# LRFDMDM register map
Vendor: Texas Instruments
Registers are 32-bit, access per field, reset 0x0 unless marked. A register's access mark holds for its fields unless they carry their own. Offsets are as the file gives them; [hi:lo] are bit positions; {n}, {i} and the like mark numbered series; 'fields as' and 'values as' point back to an identical list.

## LRFDMDM (part 2 of 3)
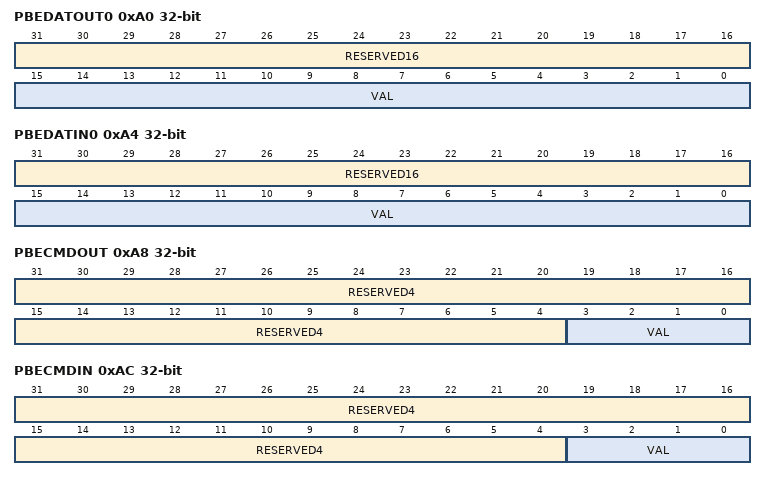
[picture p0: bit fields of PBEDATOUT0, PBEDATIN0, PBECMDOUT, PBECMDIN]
0xA0 PBEDATOUT0 — Internal. Only to be used through TI provided API.
  [31:16] RESERVED16 ro — Internal. Only to be used through TI provided API.
  [15:0] VAL rw — Internal. Only to be used through TI provided API.
    0xFFFF=ALLONES (Internal. Only to be used through TI provided API.); 0=ALLZEROS (Internal. Only to be used through TI provided API.)
0xA4 PBEDATIN0 ro — Internal. Only to be used through TI provided API.
  [31:16] RESERVED16 — Internal. Only to be used through TI provided API.
  [15:0] VAL — Internal. Only to be used through TI provided API.
    values as PBEDATOUT0.VAL
0xA8 PBECMDOUT — Internal. Only to be used through TI provided API.
  [31:4] RESERVED4 ro — Internal. Only to be used through TI provided API.
  [3:0] VAL rw — Internal. Only to be used through TI provided API.
    15=ALLONES (Internal. Only to be used through TI provided API.); 0=ALLZEROS (Internal. Only to be used through TI provided API.)
0xAC PBECMDIN ro — Internal. Only to be used through TI provided API.
  [31:4] RESERVED4 — Internal. Only to be used through TI provided API.
  [3:0] VAL — Internal. Only to be used through TI provided API.
    values as PBECMDOUT.VAL
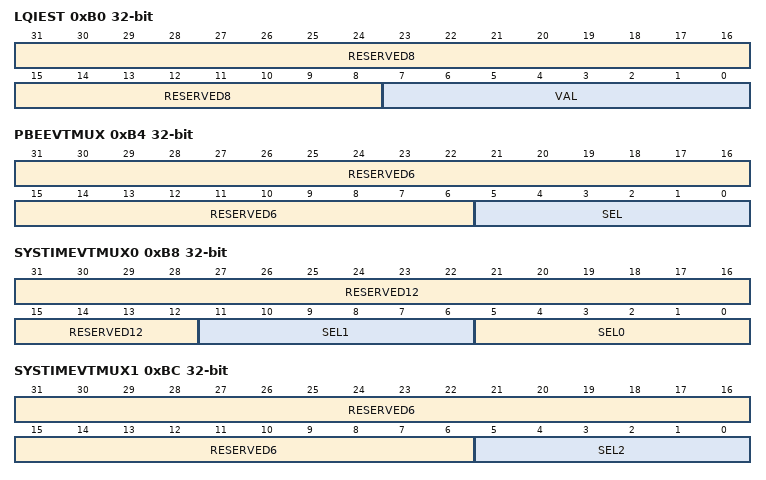
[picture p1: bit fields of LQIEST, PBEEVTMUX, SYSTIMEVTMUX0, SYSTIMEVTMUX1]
0xB0 LQIEST — Internal. Only to be used through TI provided API.
  [31:8] RESERVED8 ro — Internal. Only to be used through TI provided API.
  [7:0] VAL rw — Internal. Only to be used through TI provided API.
    255=ALLONES (Internal. Only to be used through TI provided API.); 0=ALLZEROS (Internal. Only to be used through TI provided API.)
0xB4 PBEEVTMUX — Internal. Only to be used through TI provided API.
  [31:6] RESERVED6 ro — Internal. Only to be used through TI provided API.
  [5:0] SEL rw — Internal. Only to be used through TI provided API.
    63=ALLONES (Internal. Only to be used through TI provided API.); 0=ALLZEROS (Internal. Only to be used through TI provided API.)
0xB8 SYSTIMEVTMUX0 — Internal. Only to be used through TI provided API.
  [31:12] RESERVED12 ro — Internal. Only to be used through TI provided API.
  [11:6] SEL1 rw — Internal. Only to be used through TI provided API.
    values as PBEEVTMUX.SEL
  [5:0] SEL0 rw — Internal. Only to be used through TI provided API.
    values as PBEEVTMUX.SEL
0xBC SYSTIMEVTMUX1 — Internal. Only to be used through TI provided API.
  [31:6] RESERVED6 ro — Internal. Only to be used through TI provided API.
  [5:0] SEL2 rw — Internal. Only to be used through TI provided API.
    values as PBEEVTMUX.SEL
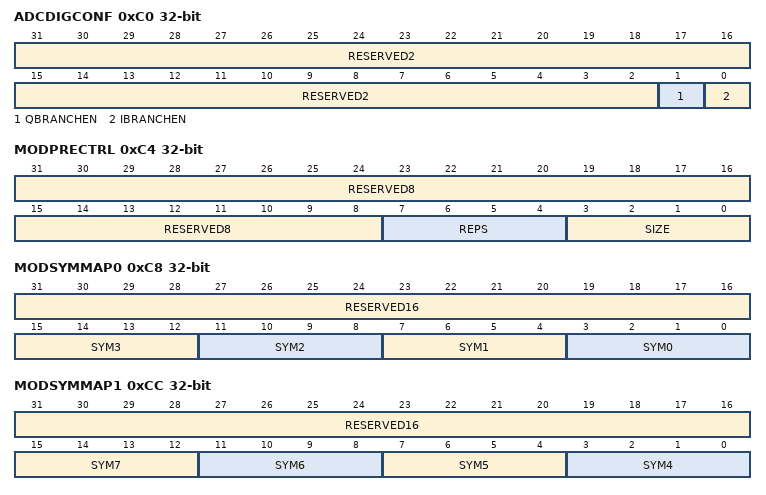
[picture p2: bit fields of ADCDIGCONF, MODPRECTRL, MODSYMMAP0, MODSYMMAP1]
0xC0 ADCDIGCONF — Internal. Only to be used through TI provided API.
  [31:2] RESERVED2 ro — Internal. Only to be used through TI provided API.
  [1] QBRANCHEN rw — Internal. Only to be used through TI provided API.
    1=ON (Internal. Only to be used through TI provided API.); 0=OFF (Internal. Only to be used through TI provided API.)
  [0] IBRANCHEN rw — Internal. Only to be used through TI provided API.
    values as QBRANCHEN
0xC4 MODPRECTRL — Internal. Only to be used through TI provided API.
  [31:8] RESERVED8 ro — Internal. Only to be used through TI provided API.
  [7:4] REPS rw — Internal. Only to be used through TI provided API.
    {v}=Internal. Only to be used through TI provided API. (v=0..15)
  [3:0] SIZE rw — Internal. Only to be used through TI provided API.
    15=BITS16 (Internal. Only to be used through TI provided API.); 7=BITS8 (Internal. Only to be used through TI provided API.); 3=BITS4 (Internal. Only to be used through TI provided API.)
0xC8 MODSYMMAP0 — Internal. Only to be used through TI provided API.
  [31:16] RESERVED16 ro — Internal. Only to be used through TI provided API.
  [4n+3:4n] SYM{n} rw (n=0..3) — Internal. Only to be used through TI provided API.
    values as PBECMDOUT.VAL
0xCC MODSYMMAP1 — Internal. Only to be used through TI provided API.
  [31:16] RESERVED16 ro — Internal. Only to be used through TI provided API.
  [4n-13:4n-16] SYM{n} rw (n=4..7) — Internal. Only to be used through TI provided API.
    values as PBECMDOUT.VAL
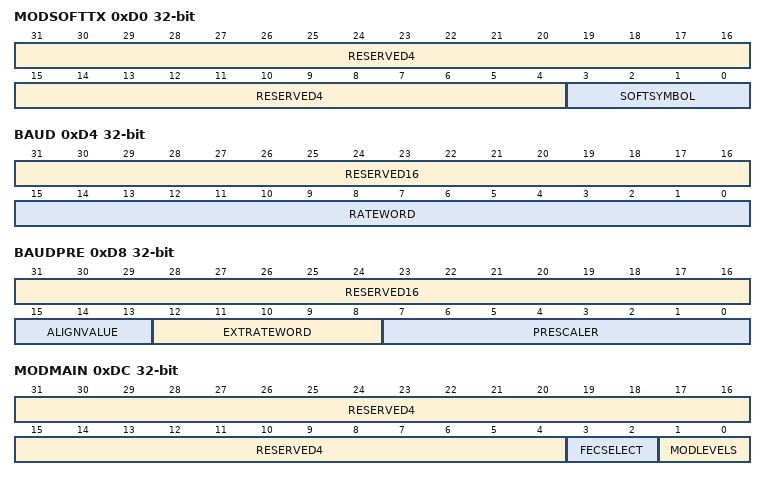
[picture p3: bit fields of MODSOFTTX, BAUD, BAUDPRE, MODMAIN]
0xD0 MODSOFTTX — Internal. Only to be used through TI provided API.
  [31:4] RESERVED4 ro — Internal. Only to be used through TI provided API.
  [3:0] SOFTSYMBOL rw — Internal. Only to be used through TI provided API.
    values as PBECMDOUT.VAL
0xD4 BAUD — Internal. Only to be used through TI provided API.
  [31:16] RESERVED16 ro — Internal. Only to be used through TI provided API.
  [15:0] RATEWORD rw — Internal. Only to be used through TI provided API.
    values as PBEDATOUT0.VAL
0xD8 BAUDPRE — Internal. Only to be used through TI provided API.
  [31:16] RESERVED16 ro — Internal. Only to be used through TI provided API.
  [15:13] ALIGNVALUE rw — Internal. Only to be used through TI provided API.
    7=ALLONES (Internal. Only to be used through TI provided API.); 0=ALLZEROS (Internal. Only to be used through TI provided API.)
  [12:8] EXTRATEWORD rw — Internal. Only to be used through TI provided API.
    31=ALLONES (Internal. Only to be used through TI provided API.); 0=ALLZEROS (Internal. Only to be used through TI provided API.)
  [7:0] PRESCALER rw — Internal. Only to be used through TI provided API.
    values as LQIEST.VAL
0xDC MODMAIN — Internal. Only to be used through TI provided API.
  [31:4] RESERVED4 ro — Internal. Only to be used through TI provided API.
  [3:2] FECSELECT rw — Internal. Only to be used through TI provided API.
    3=BLR (Internal. Only to be used through TI provided API.); 2=RESERVED (Internal. Only to be used through TI provided API.); 1=IEEE15_4 (Internal. Only to be used through TI provided API.); 0=NOSEL (Internal. Only to be used through TI provided API.)
  [1:0] MODLEVELS rw — Internal. Only to be used through TI provided API.
    2=LVL8 (Internal. Only to be used through TI provided API.); 1=LVL4 (Internal. Only to be used through TI provided API.); 0=LVL2 (Internal. Only to be used through TI provided API.)
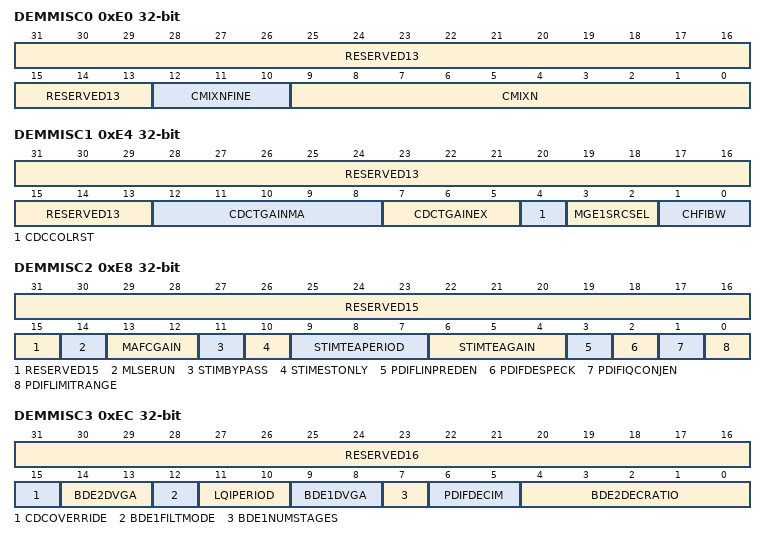
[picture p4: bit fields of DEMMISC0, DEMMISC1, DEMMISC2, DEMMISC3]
0xE0 DEMMISC0 — Internal. Only to be used through TI provided API.
  [31:13] RESERVED13 ro — Internal. Only to be used through TI provided API.
  [12:10] CMIXNFINE rw — Internal. Only to be used through TI provided API.
  [9:0] CMIXN rw — Internal. Only to be used through TI provided API.
    0x3FF=ALLONES (Internal. Only to be used through TI provided API.); 0=ALLZEROS (Internal. Only to be used through TI provided API.)
0xE4 DEMMISC1 — Internal. Only to be used through TI provided API.
  [31:13] RESERVED13 ro — Internal. Only to be used through TI provided API.
  [12:8] CDCTGAINMA rw — Internal. Only to be used through TI provided API.
    values as BAUDPRE.EXTRATEWORD
  [7:5] CDCTGAINEX rw — Internal. Only to be used through TI provided API.
    values as BAUDPRE.ALIGNVALUE
  [4] CDCCOLRST rw — Internal. Only to be used through TI provided API.
    1=EN (Internal. Only to be used through TI provided API.); 0=DIS (Internal. Only to be used through TI provided API.)
  [3:2] MGE1SRCSEL rw — Internal. Only to be used through TI provided API.
    2=CHFI (Internal. Only to be used through TI provided API.); 1=FEXB1 (Internal. Only to be used through TI provided API.); 0=FIDC (Internal. Only to be used through TI provided API.)
  [1:0] CHFIBW rw — Internal. Only to be used through TI provided API.
    3=BW0_29 (Internal. Only to be used through TI provided API.); 2=BW0_41667 (Internal. Only to be used through TI provided API.); 1=BW0_3333 (Internal. Only to be used through TI provided API.); 0=BW0_5 (Internal. Only to be used through TI provided API.)
0xE8 DEMMISC2 — Internal. Only to be used through TI provided API.
  [31:15] RESERVED15 ro — Internal. Only to be used through TI provided API.
  [14] MLSERUN rw — Internal. Only to be used through TI provided API.
    values as DEMMISC1.CDCCOLRST
  [13:12] MAFCGAIN rw — Internal. Only to be used through TI provided API.
    3=ALLONES (Internal. Only to be used through TI provided API.); 0=ALLZEROS (Internal. Only to be used through TI provided API.)
  [11] STIMBYPASS rw — Internal. Only to be used through TI provided API.
    values as DEMMISC1.CDCCOLRST
  [10] STIMESTONLY rw — Internal. Only to be used through TI provided API.
    values as DEMMISC1.CDCCOLRST
  [9:7] STIMTEAPERIOD rw — Internal. Only to be used through TI provided API.
    5=SYM128 (Internal. Only to be used through TI provided API.); 4=SYM64 (Internal. Only to be used through TI provided API.); 3=SYM32 (Internal. Only to be used through TI provided API.); 2=SYM16 (Internal. Only to be used through TI provided API.); 1=SYM8 (Internal. Only to be used through TI provided API.); 0=SYM4 (Internal. Only to be used through TI provided API.)
  [6:4] STIMTEAGAIN rw — Internal. Only to be used through TI provided API.
    7=DIV4 (Internal. Only to be used through TI provided API.); 6=DIV8 (Internal. Only to be used through TI provided API.); 5=DIV16 (Internal. Only to be used through TI provided API.); 4=DIV32 (Internal. Only to be used through TI provided API.); 3=DIV64 (Internal. Only to be used through TI provided API.); 2=DIV128 (Internal. Only to be used through TI provided API.); 1=DIV256 (Internal. Only to be used through TI provided API.); 0=DIV512 (Internal. Only to be used through TI provided API.)
  [3] PDIFLINPREDEN rw — Internal. Only to be used through TI provided API.
    values as ADCDIGCONF.QBRANCHEN
  [2] PDIFDESPECK rw — Internal. Only to be used through TI provided API.
    values as DEMMISC1.CDCCOLRST
  [1] PDIFIQCONJEN rw — Internal. Only to be used through TI provided API.
    values as ADCDIGCONF.QBRANCHEN
  [0] PDIFLIMITRANGE rw — Internal. Only to be used through TI provided API.
    values as DEMMISC1.CDCCOLRST
0xEC DEMMISC3 — Internal. Only to be used through TI provided API.
  [31:16] RESERVED16 ro — Internal. Only to be used through TI provided API.
  [15] CDCOVERRIDE rw — Internal. Only to be used through TI provided API.
  [14:13] BDE2DVGA rw — Internal. Only to be used through TI provided API.
    3=GAIN8 (Internal. Only to be used through TI provided API.); 2=GAIN4 (Internal. Only to be used through TI provided API.); 1=GAIN2 (Internal. Only to be used through TI provided API.); 0=GAIN1 (Internal. Only to be used through TI provided API.)
  [12] BDE1FILTMODE rw — Internal. Only to be used through TI provided API.
    1=DIV2 (Internal. Only to be used through TI provided API.); 0=DIV1 (Internal. Only to be used through TI provided API.)
  [11:10] LQIPERIOD rw — Internal. Only to be used through TI provided API.
    3=SYM1024 (Internal. Only to be used through TI provided API.); 2=SYM256 (Internal. Only to be used through TI provided API.); 1=SYM64 (Internal. Only to be used through TI provided API.); 0=SYM16 (Internal. Only to be used through TI provided API.)
  [9:8] BDE1DVGA rw — Internal. Only to be used through TI provided API.
    values as BDE2DVGA
  [7] BDE1NUMSTAGES rw — Internal. Only to be used through TI provided API.
    values as BDE1FILTMODE
  [6:5] PDIFDECIM rw — Internal. Only to be used through TI provided API.
    2=DIV4 (Internal. Only to be used through TI provided API.); 1=DIV2 (Internal. Only to be used through TI provided API.); 0=DIV1 (Internal. Only to be used through TI provided API.)
  [4:0] BDE2DECRATIO rw — Internal. Only to be used through TI provided API.
    3=DIV8 (Internal. Only to be used through TI provided API.); 2=DIV4 (Internal. Only to be used through TI provided API.); 1=DIV2 (Internal. Only to be used through TI provided API.); 0=DIV1 (Internal. Only to be used through TI provided API.)
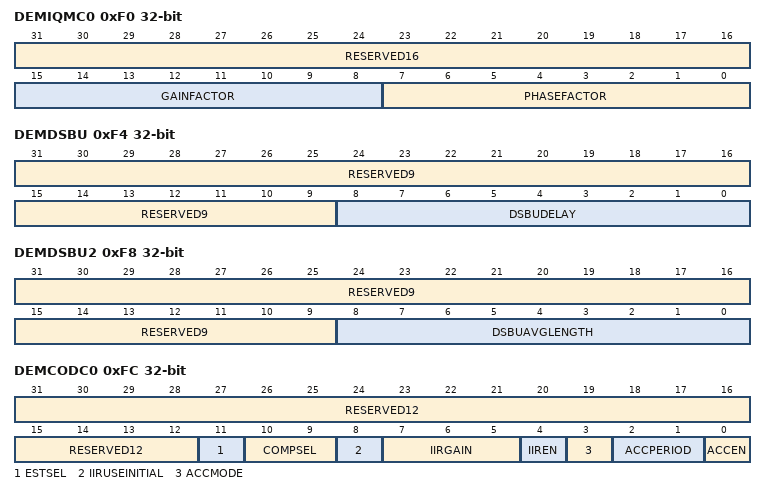
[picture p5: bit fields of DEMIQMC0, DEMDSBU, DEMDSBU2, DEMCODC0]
0xF0 DEMIQMC0 — Internal. Only to be used through TI provided API.
  [31:16] RESERVED16 ro — Internal. Only to be used through TI provided API.
  [15:8] GAINFACTOR rw — Internal. Only to be used through TI provided API.
    values as LQIEST.VAL
  [7:0] PHASEFACTOR rw — Internal. Only to be used through TI provided API.
    values as LQIEST.VAL
0xF4 DEMDSBU — Internal. Only to be used through TI provided API.
  [31:9] RESERVED9 ro — Internal. Only to be used through TI provided API.
  [8:0] DSBUDELAY rw — Internal. Only to be used through TI provided API.
    values as LQIEST.VAL
0xF8 DEMDSBU2 — Internal. Only to be used through TI provided API.
  [31:9] RESERVED9 ro — Internal. Only to be used through TI provided API.
  [8:0] DSBUAVGLENGTH rw — Internal. Only to be used through TI provided API.
0xFC DEMCODC0 — Internal. Only to be used through TI provided API.
  [31:12] RESERVED12 ro — Internal. Only to be used through TI provided API.
  [11] ESTSEL rw — Internal. Only to be used through TI provided API.
    1=IIR (Internal. Only to be used through TI provided API.); 0=ACC (Internal. Only to be used through TI provided API.)
  [10:9] COMPSEL rw — Internal. Only to be used through TI provided API.
    3=IIR (Internal. Only to be used through TI provided API.); 2=ACC (Internal. Only to be used through TI provided API.); 0=MANUAL (Internal. Only to be used through TI provided API.)
  [8] IIRUSEINITIAL rw — Internal. Only to be used through TI provided API.
    values as DEMMISC1.CDCCOLRST
  [7:5] IIRGAIN rw — Internal. Only to be used through TI provided API.
    7=DIV1024 (Internal. Only to be used through TI provided API.); 6=DIV512 (Internal. Only to be used through TI provided API.); 5=DIV256 (Internal. Only to be used through TI provided API.); 4=DIV128 (Internal. Only to be used through TI provided API.); 3=DIV64 (Internal. Only to be used through TI provided API.); 2=DIV32 (Internal. Only to be used through TI provided API.); 1=DIV16 (Internal. Only to be used through TI provided API.); 0=OFF (Internal. Only to be used through TI provided API.)
  [4] IIREN rw — Internal. Only to be used through TI provided API.
    values as ADCDIGCONF.QBRANCHEN
  [3] ACCMODE rw — Internal. Only to be used through TI provided API.
    1=CONT (Internal. Only to be used through TI provided API.); 0=SINGLE (Internal. Only to be used through TI provided API.)
  [2:1] ACCPERIOD rw — Internal. Only to be used through TI provided API.
    3=SMPL512 (Internal. Only to be used through TI provided API.); 2=SMPL128 (Internal. Only to be used through TI provided API.); 1=SMPL32 (Internal. Only to be used through TI provided API.); 0=SMPL8 (Internal. Only to be used through TI provided API.)
  [0] ACCEN rw — Internal. Only to be used through TI provided API.
    values as ADCDIGCONF.QBRANCHEN
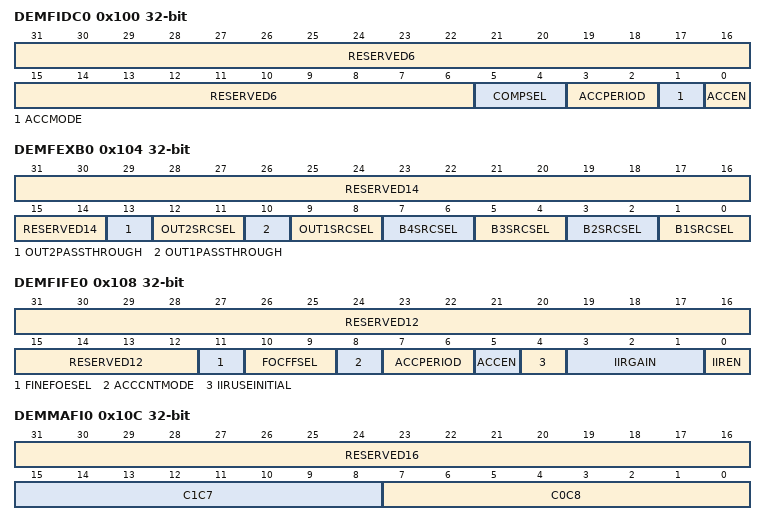
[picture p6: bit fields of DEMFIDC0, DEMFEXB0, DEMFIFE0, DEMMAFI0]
0x100 DEMFIDC0 — Internal. Only to be used through TI provided API.
  [31:6] RESERVED6 ro — Internal. Only to be used through TI provided API.
  [5:4] COMPSEL rw — Internal. Only to be used through TI provided API.
    2=ACC (Internal. Only to be used through TI provided API.); 0=MANUAL (Internal. Only to be used through TI provided API.)
  [3:2] ACCPERIOD rw — Internal. Only to be used through TI provided API.
    values as DEMCODC0.ACCPERIOD
  [1] ACCMODE rw — Internal. Only to be used through TI provided API.
    values as DEMCODC0.ACCMODE
  [0] ACCEN rw — Internal. Only to be used through TI provided API.
    values as ADCDIGCONF.QBRANCHEN
0x104 DEMFEXB0 — Internal. Only to be used through TI provided API.
  [31:14] RESERVED14 ro — Internal. Only to be used through TI provided API.
  [13] OUT2PASSTHROUGH rw — Internal. Only to be used through TI provided API.
    1=ONE (Internal. Only to be used through TI provided API.); 0=ZERO (Internal. Only to be used through TI provided API.)
  [12:11] OUT2SRCSEL rw — Internal. Only to be used through TI provided API.
    2=BDE1 (Internal. Only to be used through TI provided API.); 1=CMIX (Internal. Only to be used through TI provided API.); 0=CODC (Internal. Only to be used through TI provided API.)
  [10] OUT1PASSTHROUGH rw — Internal. Only to be used through TI provided API.
    values as OUT2PASSTHROUGH
  [9:8] OUT1SRCSEL rw — Internal. Only to be used through TI provided API.
    values as OUT2SRCSEL
  [7:6] B4SRCSEL rw — Internal. Only to be used through TI provided API.
    3=ONES (Internal. Only to be used through TI provided API.); 0=ZEROS (Internal. Only to be used through TI provided API.)
  [5:4] B3SRCSEL rw — Internal. Only to be used through TI provided API.
    2=CMIX (Internal. Only to be used through TI provided API.); 1=CODC (Internal. Only to be used through TI provided API.); 0=INPUT (Internal. Only to be used through TI provided API.)
  [3:2] B2SRCSEL rw — Internal. Only to be used through TI provided API.
    2=BDE1 (Internal. Only to be used through TI provided API.); 1=CODC (Internal. Only to be used through TI provided API.); 0=INPUT (Internal. Only to be used through TI provided API.)
  [1:0] B1SRCSEL rw — Internal. Only to be used through TI provided API.
    2=BDE1 (Internal. Only to be used through TI provided API.); 1=CMIX (Internal. Only to be used through TI provided API.); 0=INPUT (Internal. Only to be used through TI provided API.)
0x108 DEMFIFE0 — Internal. Only to be used through TI provided API.
  [31:12] RESERVED12 ro — Internal. Only to be used through TI provided API.
  [11] FINEFOESEL rw — Internal. Only to be used through TI provided API.
    1=ACC (Internal. Only to be used through TI provided API.); 0=IIR (Internal. Only to be used through TI provided API.)
  [10:9] FOCFFSEL rw — Internal. Only to be used through TI provided API.
    2=MANUAL (Internal. Only to be used through TI provided API.); 1=ACC (Internal. Only to be used through TI provided API.); 0=IIR (Internal. Only to be used through TI provided API.)
  [8] ACCCNTMODE rw — Internal. Only to be used through TI provided API.
    values as DEMCODC0.ACCMODE
  [7:6] ACCPERIOD rw — Internal. Only to be used through TI provided API.
    3=PER512 (Internal. Only to be used through TI provided API.); 2=PER256 (Internal. Only to be used through TI provided API.); 1=PER128 (Internal. Only to be used through TI provided API.); 0=PER64 (Internal. Only to be used through TI provided API.)
  [5] ACCEN rw — Internal. Only to be used through TI provided API.
    values as ADCDIGCONF.QBRANCHEN
  [4] IIRUSEINITIAL rw — Internal. Only to be used through TI provided API.
    values as DEMMISC1.CDCCOLRST
  [3:1] IIRGAIN rw — Internal. Only to be used through TI provided API.
    values as DEMCODC0.IIRGAIN
  [0] IIREN rw — Internal. Only to be used through TI provided API.
    values as ADCDIGCONF.QBRANCHEN
0x10C DEMMAFI0 — Internal. Only to be used through TI provided API.
  [31:16] RESERVED16 ro — Internal. Only to be used through TI provided API.
  [15:8] C1C7 rw — Internal. Only to be used through TI provided API.
    values as LQIEST.VAL
  [7:0] C0C8 rw — Internal. Only to be used through TI provided API.
    values as LQIEST.VAL
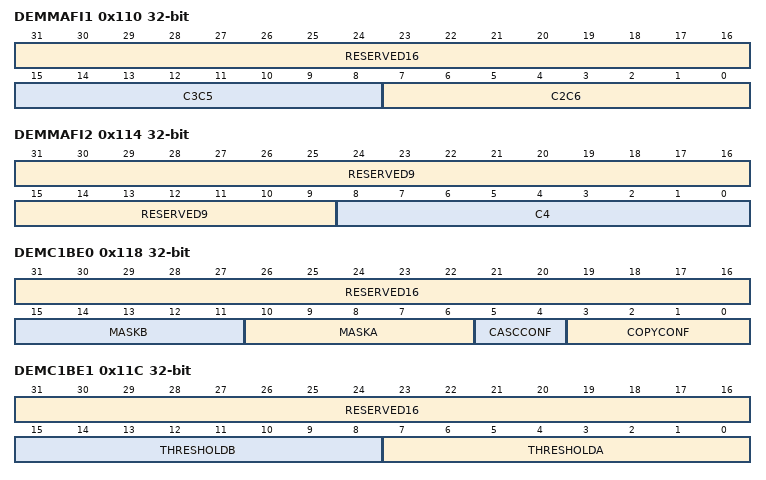
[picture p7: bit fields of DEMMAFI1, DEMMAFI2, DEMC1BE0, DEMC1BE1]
0x110 DEMMAFI1 — Internal. Only to be used through TI provided API.
  [31:16] RESERVED16 ro — Internal. Only to be used through TI provided API.
  [15:8] C3C5 rw — Internal. Only to be used through TI provided API.
    values as LQIEST.VAL
  [7:0] C2C6 rw — Internal. Only to be used through TI provided API.
    values as LQIEST.VAL
0x114 DEMMAFI2 — Internal. Only to be used through TI provided API.
  [31:9] RESERVED9 ro — Internal. Only to be used through TI provided API.
  [8:0] C4 rw — Internal. Only to be used through TI provided API.
    0x1FF=ALLONES (Internal. Only to be used through TI provided API.); 0=ALLZEROS (Internal. Only to be used through TI provided API.)
0x118 DEMC1BE0 — Internal. Only to be used through TI provided API.
  [31:16] RESERVED16 ro — Internal. Only to be used through TI provided API.
  [15:11] MASKB rw — Internal. Only to be used through TI provided API.
    values as BAUDPRE.EXTRATEWORD
  [10:6] MASKA rw — Internal. Only to be used through TI provided API.
    values as BAUDPRE.EXTRATEWORD
  [5:4] CASCCONF rw — Internal. Only to be used through TI provided API.
    2=PARALLEL (Internal. Only to be used through TI provided API.); 1=SERIAL (Internal. Only to be used through TI provided API.); 0=SINGLE (Internal. Only to be used through TI provided API.)
  [3:0] COPYCONF rw — Internal. Only to be used through TI provided API.
    values as PBECMDOUT.VAL
0x11C DEMC1BE1 — Internal. Only to be used through TI provided API.
  [31:16] RESERVED16 ro — Internal. Only to be used through TI provided API.
  [15:8] THRESHOLDB rw — Internal. Only to be used through TI provided API.
    values as LQIEST.VAL
  [7:0] THRESHOLDA rw — Internal. Only to be used through TI provided API.
    values as LQIEST.VAL
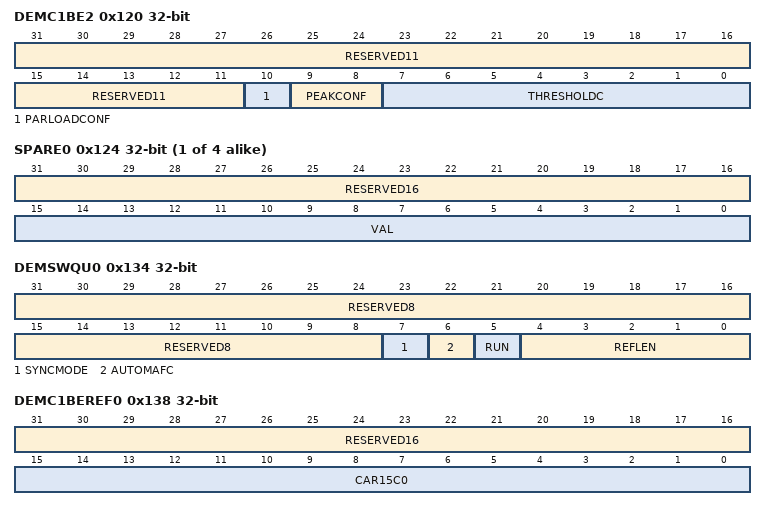
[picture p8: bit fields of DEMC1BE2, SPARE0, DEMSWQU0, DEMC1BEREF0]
0x120 DEMC1BE2 — Internal. Only to be used through TI provided API.
  [31:11] RESERVED11 ro — Internal. Only to be used through TI provided API.
  [10] PARLOADCONF rw — Internal. Only to be used through TI provided API.
    1=ATOD (Internal. Only to be used through TI provided API.); 0=ATOB (Internal. Only to be used through TI provided API.)
  [9:8] PEAKCONF rw — Internal. Only to be used through TI provided API.
    2=BESTAB (Internal. Only to be used through TI provided API.); 1=BEST (Internal. Only to be used through TI provided API.); 0=THRESH (Internal. Only to be used through TI provided API.)
  [7:0] THRESHOLDC rw — Internal. Only to be used through TI provided API.
    values as LQIEST.VAL
{0x124+4i} SPARE{i} (i=0..3) — Internal. Only to be used through TI provided API.
  fields as PBEDATOUT0
0x134 DEMSWQU0 — Internal. Only to be used through TI provided API.
  [31:8] RESERVED8 ro — Internal. Only to be used through TI provided API.
  [7] SYNCMODE rw — Internal. Only to be used through TI provided API.
    values as DEMFEXB0.OUT2PASSTHROUGH
  [6] AUTOMAFC rw — Internal. Only to be used through TI provided API.
    values as ADCDIGCONF.QBRANCHEN
  [5] RUN rw — Internal. Only to be used through TI provided API.
    values as ADCDIGCONF.QBRANCHEN
  [4:0] REFLEN rw — Internal. Only to be used through TI provided API.
    values as BAUDPRE.EXTRATEWORD
0x138 DEMC1BEREF0 — Internal. Only to be used through TI provided API.
  [31:16] RESERVED16 ro — Internal. Only to be used through TI provided API.
  [15:0] CAR15C0 rw — Internal. Only to be used through TI provided API.
    values as PBEDATOUT0.VAL
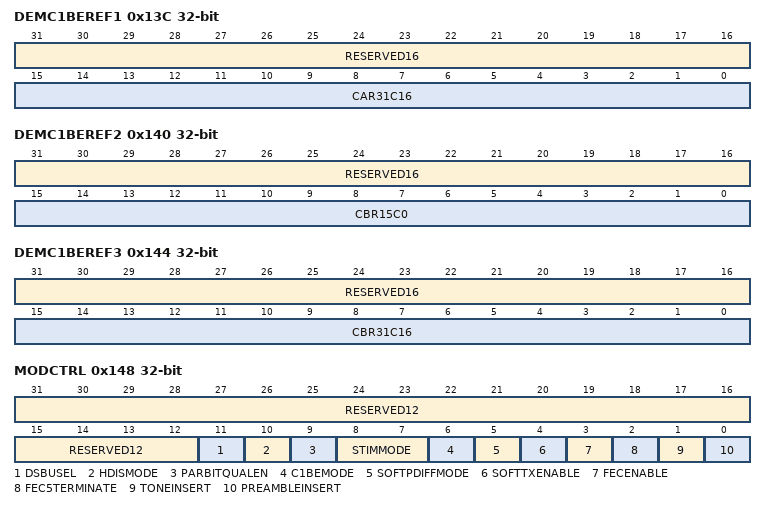
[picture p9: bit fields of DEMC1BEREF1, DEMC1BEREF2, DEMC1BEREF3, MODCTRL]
0x13C DEMC1BEREF1 — Internal. Only to be used through TI provided API.
  [31:16] RESERVED16 ro — Internal. Only to be used through TI provided API.
  [15:0] CAR31C16 rw — Internal. Only to be used through TI provided API.
    values as PBEDATOUT0.VAL
0x140 DEMC1BEREF2 — Internal. Only to be used through TI provided API.
  [31:16] RESERVED16 ro — Internal. Only to be used through TI provided API.
  [15:0] CBR15C0 rw — Internal. Only to be used through TI provided API.
    values as PBEDATOUT0.VAL
0x144 DEMC1BEREF3 — Internal. Only to be used through TI provided API.
  [31:16] RESERVED16 ro — Internal. Only to be used through TI provided API.
  [15:0] CBR31C16 rw — Internal. Only to be used through TI provided API.
    values as PBEDATOUT0.VAL
0x148 MODCTRL — Internal. Only to be used through TI provided API.
  [31:12] RESERVED12 ro — Internal. Only to be used through TI provided API.
  [11] DSBUSEL rw — Internal. Only to be used through TI provided API.
    values as DEMFEXB0.OUT2PASSTHROUGH
  [10] HDISMODE rw — Internal. Only to be used through TI provided API.
    values as DEMMISC1.CDCCOLRST
  [9] PARBITQUALEN rw — Internal. Only to be used through TI provided API.
    values as ADCDIGCONF.QBRANCHEN
  [8:7] STIMMODE rw — Internal. Only to be used through TI provided API.
    2=EARLY (Internal. Only to be used through TI provided API.); 1=LATE (Internal. Only to be used through TI provided API.); 0=NORMAL (Internal. Only to be used through TI provided API.)
  [6] C1BEMODE rw — Internal. Only to be used through TI provided API.
    1=EARLYLATE (Internal. Only to be used through TI provided API.); 0=NORMAL (Internal. Only to be used through TI provided API.)
  [5] SOFTPDIFFMODE rw — Internal. Only to be used through TI provided API.
    values as DEMMISC1.CDCCOLRST
  [4] SOFTTXENABLE rw — Internal. Only to be used through TI provided API.
    values as ADCDIGCONF.QBRANCHEN
  [3] FECENABLE rw — Internal. Only to be used through TI provided API.
    values as ADCDIGCONF.QBRANCHEN
  [2] FEC5TERMINATE rw — Internal. Only to be used through TI provided API.
    values as ADCDIGCONF.QBRANCHEN
  [1] TONEINSERT rw — Internal. Only to be used through TI provided API.
    values as DEMMISC1.CDCCOLRST
  [0] PREAMBLEINSERT rw — Internal. Only to be used through TI provided API.
    values as DEMMISC1.CDCCOLRST
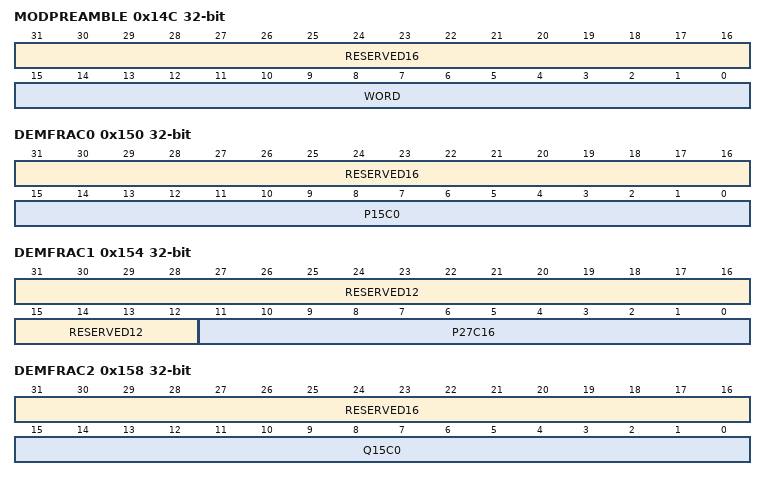
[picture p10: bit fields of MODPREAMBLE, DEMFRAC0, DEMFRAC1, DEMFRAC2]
0x14C MODPREAMBLE — Internal. Only to be used through TI provided API.
  [31:16] RESERVED16 ro — Internal. Only to be used through TI provided API.
  [15:0] WORD rw — Internal. Only to be used through TI provided API.
    values as PBEDATOUT0.VAL
0x150 DEMFRAC0 — Internal. Only to be used through TI provided API.
  [31:16] RESERVED16 ro — Internal. Only to be used through TI provided API.
  [15:0] P15C0 rw — Internal. Only to be used through TI provided API.
    values as PBEDATOUT0.VAL
0x154 DEMFRAC1 — Internal. Only to be used through TI provided API.
  [31:12] RESERVED12 ro — Internal. Only to be used through TI provided API.
  [11:0] P27C16 rw — Internal. Only to be used through TI provided API.
    0xFFF=ALLONES (Internal. Only to be used through TI provided API.); 0=ALLZEROS (Internal. Only to be used through TI provided API.)
0x158 DEMFRAC2 — Internal. Only to be used through TI provided API.
  [31:16] RESERVED16 ro — Internal. Only to be used through TI provided API.
  [15:0] Q15C0 rw — Internal. Only to be used through TI provided API.
    values as PBEDATOUT0.VAL
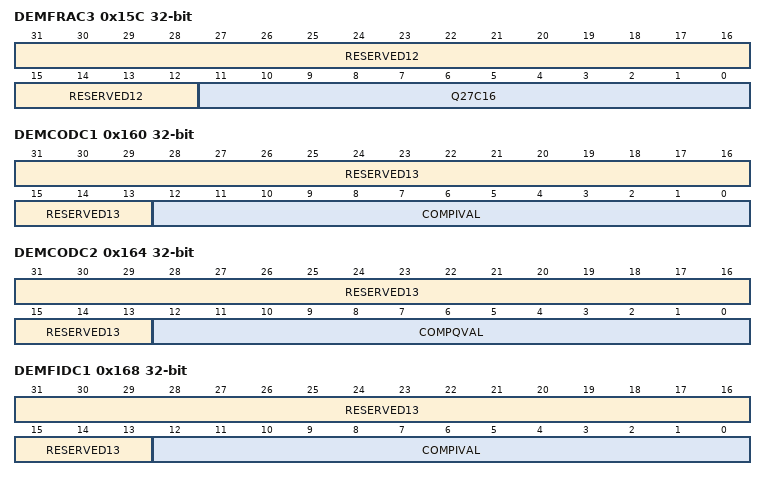
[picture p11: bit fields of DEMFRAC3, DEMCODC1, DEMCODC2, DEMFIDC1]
0x15C DEMFRAC3 — Internal. Only to be used through TI provided API.
  [31:12] RESERVED12 ro — Internal. Only to be used through TI provided API.
  [11:0] Q27C16 rw — Internal. Only to be used through TI provided API.
    values as DEMFRAC1.P27C16
0x160 DEMCODC1 — Internal. Only to be used through TI provided API.
  [31:13] RESERVED13 ro — Internal. Only to be used through TI provided API.
  [12:0] COMPIVAL rw — Internal. Only to be used through TI provided API.
    0x1FFF=ALLONES (Internal. Only to be used through TI provided API.); 0=ALLZEROS (Internal. Only to be used through TI provided API.)
0x164 DEMCODC2 — Internal. Only to be used through TI provided API.
  [31:13] RESERVED13 ro — Internal. Only to be used through TI provided API.
  [12:0] COMPQVAL rw — Internal. Only to be used through TI provided API.
    values as DEMCODC1.COMPIVAL
0x168 DEMFIDC1 — Internal. Only to be used through TI provided API.
  fields as DEMCODC1
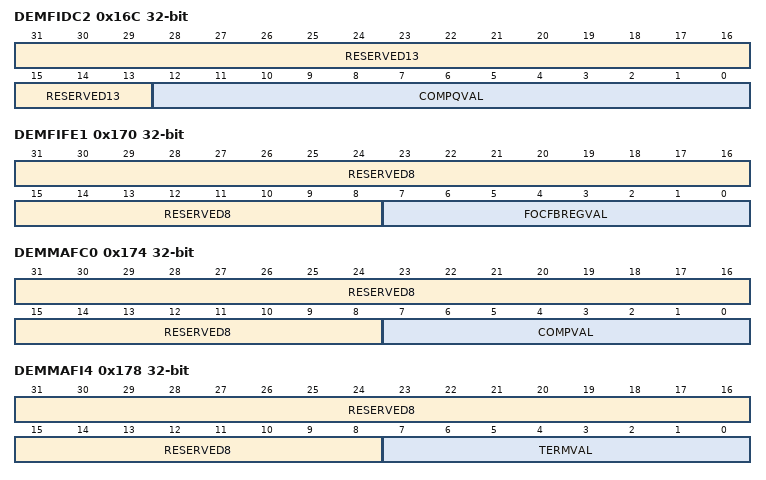
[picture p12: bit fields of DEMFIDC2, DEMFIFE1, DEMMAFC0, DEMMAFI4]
0x16C DEMFIDC2 — Internal. Only to be used through TI provided API.
  fields as DEMCODC2
0x170 DEMFIFE1 — Internal. Only to be used through TI provided API.
  [31:8] RESERVED8 ro — Internal. Only to be used through TI provided API.
  [7:0] FOCFBREGVAL rw — Internal. Only to be used through TI provided API.
    values as LQIEST.VAL
0x174 DEMMAFC0 — Internal. Only to be used through TI provided API.
  [31:8] RESERVED8 ro — Internal. Only to be used through TI provided API.
  [7:0] COMPVAL rw — Internal. Only to be used through TI provided API.
    values as LQIEST.VAL
0x178 DEMMAFI4 — Internal. Only to be used through TI provided API.
  [31:8] RESERVED8 ro — Internal. Only to be used through TI provided API.
  [7:0] TERMVAL rw — Internal. Only to be used through TI provided API.
    values as LQIEST.VAL
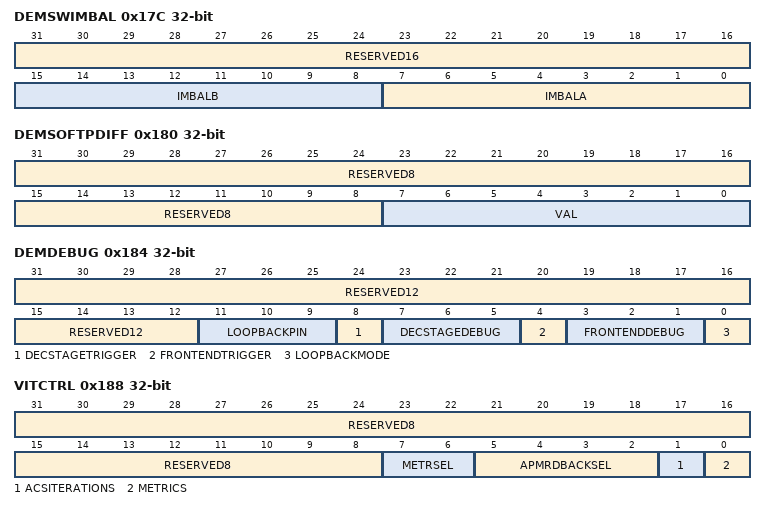
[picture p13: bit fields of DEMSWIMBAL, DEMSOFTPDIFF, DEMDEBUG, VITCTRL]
0x17C DEMSWIMBAL — Internal. Only to be used through TI provided API.
  [31:16] RESERVED16 ro — Internal. Only to be used through TI provided API.
  [15:8] IMBALB rw — Internal. Only to be used through TI provided API.
    values as LQIEST.VAL
  [7:0] IMBALA rw — Internal. Only to be used through TI provided API.
    values as LQIEST.VAL
0x180 DEMSOFTPDIFF — Internal. Only to be used through TI provided API.
  fields as LQIEST
0x184 DEMDEBUG — Internal. Only to be used through TI provided API.
  [31:12] RESERVED12 ro — Internal. Only to be used through TI provided API.
  [11:9] LOOPBACKPIN rw — Internal. Only to be used through TI provided API.
    {v}=GPI{v} (Internal. Only to be used through TI provided API.) (v=0..7)
  [8] DECSTAGETRIGGER rw — Internal. Only to be used through TI provided API.
    values as DEMFEXB0.OUT2PASSTHROUGH
  [7:5] DECSTAGEDEBUG rw — Internal. Only to be used through TI provided API.
    7=SOFD (Internal. Only to be used through TI provided API.); 6=STIM (Internal. Only to be used through TI provided API.); 5=MAFC (Internal. Only to be used through TI provided API.); 4=C1BE (Internal. Only to be used through TI provided API.); 3=MAFI (Internal. Only to be used through TI provided API.); 2=FIFE (Internal. Only to be used through TI provided API.); 1=PDIF (Internal. Only to be used through TI provided API.); 0=NOSEL (Internal. Only to be used through TI provided API.)
  [4] FRONTENDTRIGGER rw — Internal. Only to be used through TI provided API.
    values as DEMFEXB0.OUT2PASSTHROUGH
  [3:1] FRONTENDDEBUG rw — Internal. Only to be used through TI provided API.
    7=FIDC (Internal. Only to be used through TI provided API.); 6=FRAC (Internal. Only to be used through TI provided API.); 5=CHFI (Internal. Only to be used through TI provided API.); 4=BDE2 (Internal. Only to be used through TI provided API.); 3=FEXB2 (Internal. Only to be used through TI provided API.); 2=BDE1 (Internal. Only to be used through TI provided API.); 1=IQMC (Internal. Only to be used through TI provided API.); 0=NOSEL (Internal. Only to be used through TI provided API.)
  [0] LOOPBACKMODE rw — Internal. Only to be used through TI provided API.
    values as DEMFEXB0.OUT2PASSTHROUGH
0x188 VITCTRL — Internal. Only to be used through TI provided API.
  [31:8] RESERVED8 ro — Internal. Only to be used through TI provided API.
  [7:6] METRSEL rw — Internal. Only to be used through TI provided API.
    3=MLSE (Internal. Only to be used through TI provided API.); 2=SOFD (Internal. Only to be used through TI provided API.); 1=PHAC (Internal. Only to be used through TI provided API.); 0=MET5M (Internal. Only to be used through TI provided API.)
  [5:2] APMRDBACKSEL rw — Internal. Only to be used through TI provided API.
    {v}=APM{v-8} (Internal. Only to be used through TI provided API.) (v=8..15); 0=NOSEL (Internal. Only to be used through TI provided API.)
  [1] ACSITERATIONS rw — Internal. Only to be used through TI provided API.
    1=CODE23 (Internal. Only to be used through TI provided API.); 0=CODE12 (Internal. Only to be used through TI provided API.)
  [0] METRICS rw — Internal. Only to be used through TI provided API.
    1=SOFT (Internal. Only to be used through TI provided API.); 0=HW (Internal. Only to be used through TI provided API.)
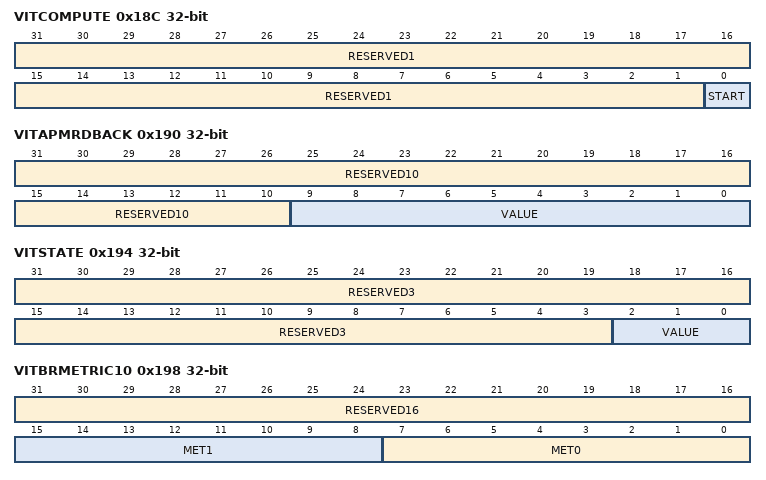
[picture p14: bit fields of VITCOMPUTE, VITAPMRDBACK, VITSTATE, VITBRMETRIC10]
0x18C VITCOMPUTE — Internal. Only to be used through TI provided API.
  [31:1] RESERVED1 ro — Internal. Only to be used through TI provided API.
  [0] START wo — Internal. Only to be used through TI provided API.
    values as DEMFEXB0.OUT2PASSTHROUGH
0x190 VITAPMRDBACK ro — Internal. Only to be used through TI provided API.
  [31:10] RESERVED10 — Internal. Only to be used through TI provided API.
  [9:0] VALUE — Internal. Only to be used through TI provided API.
    values as DEMMISC0.CMIXN
0x194 VITSTATE ro — Internal. Only to be used through TI provided API.
  [31:3] RESERVED3 — Internal. Only to be used through TI provided API.
  [2:0] VALUE — Internal. Only to be used through TI provided API.
    values as BAUDPRE.ALIGNVALUE
0x198 VITBRMETRIC10 — Internal. Only to be used through TI provided API.
  [31:16] RESERVED16 ro — Internal. Only to be used through TI provided API.
  [15:8] MET1 rw — Internal. Only to be used through TI provided API.
    values as LQIEST.VAL
  [7:0] MET0 rw — Internal. Only to be used through TI provided API.
    values as LQIEST.VAL
